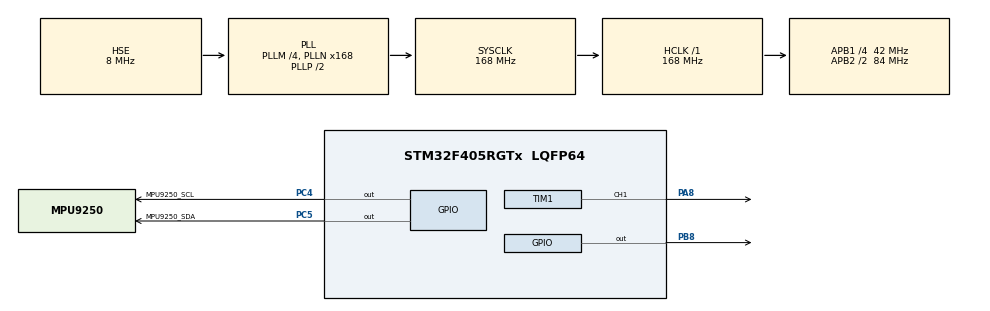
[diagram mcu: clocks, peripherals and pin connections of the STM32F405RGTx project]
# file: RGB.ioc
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Dma.Request0=TIM1_CH1
Dma.TIM1_CH1.0.Direction=DMA_MEMORY_TO_PERIPH
Dma.TIM1_CH1.0.FIFOMode=DMA_FIFOMODE_DISABLE
Dma.TIM1_CH1.0.Instance=DMA2_Stream1
Dma.TIM1_CH1.0.MemDataAlignment=DMA_MDATAALIGN_WORD
Dma.TIM1_CH1.0.MemInc=DMA_MINC_ENABLE
Dma.TIM1_CH1.0.Mode=DMA_NORMAL
Dma.TIM1_CH1.0.PeriphDataAlignment=DMA_PDATAALIGN_WORD
Dma.TIM1_CH1.0.PeriphInc=DMA_PINC_DISABLE
Dma.TIM1_CH1.0.Priority=DMA_PRIORITY_MEDIUM
Mcu.Family=STM32F4
Mcu.Name=STM32F405RGTx
Mcu.Package=LQFP64
NVIC.DMA2_Stream1_IRQn=true\:0\:0\:false\:false\:true\:false\:true\:true
NVIC.PriorityGroup=NVIC_PRIORITYGROUP_4
PA13.Mode=Serial_Wire
PA13.Signal=SYS_JTMS-SWDIO
PA14.Mode=Serial_Wire
PA14.Signal=SYS_JTCK-SWCLK
PA8.Signal=S_TIM1_CH1
PB8.Signal=GPIO_Output
PC4.GPIO_Label=MPU9250_SCL
PC4.Signal=GPIO_Output
PC5.GPIO_Label=MPU9250_SDA
PC5.PinState=GPIO_PIN_SET
PC5.Signal=GPIO_Output
PH0-OSC_IN.Mode=HSE-External-Oscillator
PH0-OSC_IN.Signal=RCC_OSC_IN
PH1-OSC_OUT.Mode=HSE-External-Oscillator
PH1-OSC_OUT.Signal=RCC_OSC_OUT
ProjectManager.HeapSize=0x200
ProjectManager.StackSize=0x400
ProjectManager.TargetToolchain=MDK-ARM V5.32
RCC.48MHZClocksFreq_Value=84000000
RCC.AHBFreq_Value=168000000
RCC.APB1CLKDivider=RCC_HCLK_DIV4
RCC.APB1Freq_Value=42000000
RCC.APB1TimFreq_Value=84000000
RCC.APB2CLKDivider=RCC_HCLK_DIV2
RCC.APB2Freq_Value=84000000
RCC.APB2TimFreq_Value=168000000
RCC.CortexFreq_Value=168000000
RCC.HCLKFreq_Value=168000000
RCC.HSE_VALUE=8000000
RCC.HSI_VALUE=16000000
RCC.LSE_VALUE=32768
RCC.PLLM=4
RCC.PLLN=168
RCC.PLLSourceVirtual=RCC_PLLSOURCE_HSE
RCC.SYSCLKFreq_VALUE=168000000
RCC.SYSCLKSource=RCC_SYSCLKSOURCE_PLLCLK
RCC.VCOOutputFreq_Value=336000000
SH.S_TIM1_CH1.0=TIM1_CH1,PWM Generation1 CH1
TIM1.Channel-PWM\ Generation1\ CH1=TIM_CHANNEL_1
TIM1.Period=210
TIM14.Prescaler=168
VP_TIM14_VS_ClockSourceINT.Mode=Enable_Timer
VP_TIM1_VS_ClockSourceINT.Mode=Internal
board=custom

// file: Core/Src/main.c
/* USER CODE BEGIN Header */
/**
  ******************************************************************************
  * @file           : main.c
  * @brief          : Main program body
  ******************************************************************************
  * @attention
  *
  * Copyright (c) 2024 STMicroelectronics.
  * All rights reserved.
  *
  * This software is licensed under terms that can be found in the LICENSE file
  * in the root directory of this software component.
  * If no LICENSE file comes with this software, it is provided AS-IS.
  *
  ******************************************************************************
  */
/* USER CODE END Header */
#include "main.h"
#include "dma.h"
#include "tim.h"
#include "gpio.h"

/* USER CODE BEGIN Includes */
#include "RGB.h"

/* USER CODE END Includes */

void SystemClock_Config(void);

int main(void)
{

  /* MCU Configuration--------------------------------------------------------*/

  /* Reset of all peripherals, Initializes the Flash interface and the Systick. */
  HAL_Init();

  /* Configure the system clock */
  SystemClock_Config();

  /* Initialize all configured peripherals */
  MX_GPIO_Init();
  MX_DMA_Init();
  MX_TIM1_Init();
  MX_TIM14_Init();

  /* Infinite loop */
  while (1)
  {

    /* USER CODE BEGIN 3 */

	  RGB_Show_64();				//调用RGB灯板显示函数
      HAL_Delay(10);				//延时200ms
//	  test();
  }
  /* USER CODE END 3 */
}

void SystemClock_Config(void)
{
  RCC_OscInitTypeDef RCC_OscInitStruct = {0};
  RCC_ClkInitTypeDef RCC_ClkInitStruct = {0};

  /** Configure the main internal regulator output voltage
  */
  __HAL_RCC_PWR_CLK_ENABLE();
  __HAL_PWR_VOLTAGESCALING_CONFIG(PWR_REGULATOR_VOLTAGE_SCALE1);

  /** Initializes the RCC Oscillators according to the specified parameters
  * in the RCC_OscInitTypeDef structure.
  */
  RCC_OscInitStruct.OscillatorType = RCC_OSCILLATORTYPE_HSE;
  RCC_OscInitStruct.HSEState = RCC_HSE_ON;
  RCC_OscInitStruct.PLL.PLLState = RCC_PLL_ON;
  RCC_OscInitStruct.PLL.PLLSource = RCC_PLLSOURCE_HSE;
  RCC_OscInitStruct.PLL.PLLM = 4;
  RCC_OscInitStruct.PLL.PLLN = 168;
  RCC_OscInitStruct.PLL.PLLP = RCC_PLLP_DIV2;
  RCC_OscInitStruct.PLL.PLLQ = 4;
  if (HAL_RCC_OscConfig(&RCC_OscInitStruct) != HAL_OK)
  {
    Error_Handler();
  }

  /** Initializes the CPU, AHB and APB buses clocks
  */
  RCC_ClkInitStruct.ClockType = RCC_CLOCKTYPE_HCLK|RCC_CLOCKTYPE_SYSCLK
                              |RCC_CLOCKTYPE_PCLK1|RCC_CLOCKTYPE_PCLK2;
  RCC_ClkInitStruct.SYSCLKSource = RCC_SYSCLKSOURCE_PLLCLK;
  RCC_ClkInitStruct.AHBCLKDivider = RCC_SYSCLK_DIV1;
  RCC_ClkInitStruct.APB1CLKDivider = RCC_HCLK_DIV4;
  RCC_ClkInitStruct.APB2CLKDivider = RCC_HCLK_DIV2;

  if (HAL_RCC_ClockConfig(&RCC_ClkInitStruct, FLASH_LATENCY_5) != HAL_OK)
  {
    Error_Handler();
  }
}

void Error_Handler(void)
{
  __disable_irq();
  while (1)
  {
  }
}
